# LKS32MC07x register map
Vendor: Linko Ltd.; Series: LKS32MC07x; File version: 1.0
CPU: CM0 r1p0, little endian, MPU, no FPU, 3 interrupt priority bits
Registers are 32-bit, read-write, reset 0x0 unless marked. A register's access mark holds for its fields unless they carry their own. Offsets are from the block's base; [hi:lo] are bit positions; {n}, {i} and the like mark numbered series; 'fields as' and 'values as' point back to an identical list.

## DMA0 — DMA0 registers
Base 0x40011200
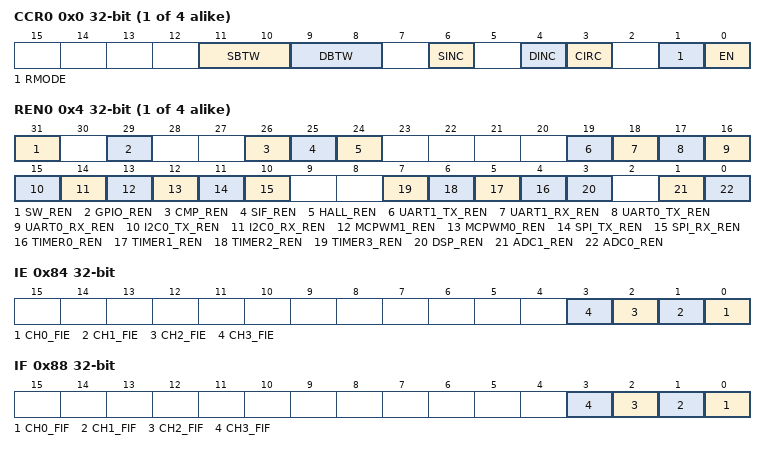
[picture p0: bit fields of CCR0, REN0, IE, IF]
{0x0+0x20*i} CCR{i} (i=0..3) — DMA channel {i} configuration
  [11:10] SBTW — Source data width
    0=BYTE (8bit byte); 1=HALFWORD (16bit halfword); 2=WORD (32bit word)
  [9:8] DBTW — Destination data width
    values as SBTW
  [6] SINC — Source Address Incremental
    0=NINC (Source addr will be increased by SBTW each transfer); 1=INC (Description addr will be increased by DBTW each transfer)
  [4] DINC — Destination Address Incremental
    values as SINC
  [3] CIRC — circular mode
    0=NORMAL (Normal mode); 1=CIRC (Circular mode)
  [1] RMODE — Round mode
    0=SINGLE (Single round, multi-times); 1=MULTI (Multi-round, single time per round)
  [0] EN — channel enable
    0=DISABLED (Channel is disabled); 1=ENABLED (Channel is enabled)
{0x4+0x20*i} REN{i} (i=0..3) — DMA channel {i} request enable
  [31] SW_REN — Software trigger enable
  [29] GPIO_REN — GPIO trigger enable
  [26] CMP_REN — CMP trigger enable
  [25] SIF_REN — SIF trigger enable
  [24] HALL_REN — HALL trigger enable
  [19] UART1_TX_REN — UART1_TX trigger enable
  [18] UART1_RX_REN — UART1_RX trigger enable
  [17] UART0_TX_REN — UART0_TX trigger enable
  [16] UART0_RX_REN — UART0_RX trigger enable
  [15] I2C0_TX_REN — I2C0_TX trigger enable
  [14] I2C0_RX_REN — I2C0_RX trigger enable
  [13] MCPWM1_REN — MCPWM trigger 1 enable
  [12] MCPWM0_REN — MCPWM trigger 0 enable
  [11] SPI_TX_REN — SPI_TX trigger enable
  [10] SPI_RX_REN — SPI_RX trigger enable
  [n+4] TIMER{n}_REN (n=0..3) — TIMER{n} trigger enable
  [3] DSP_REN — DSP trigger enable
  [1] ADC1_REN — ADC1 trigger enable
  [0] ADC0_REN — ADC0 trigger enable
{0x8+0x20*i} CTMS{i} (i=0..3) — DMA channel {i} transmission times
  [7:0] TMS — times or rounds
{0xC+0x20*i} SADR{i} (i=0..3) — DMA channel {i} source address
  [31:0] ADDR — Source Address
{0x10+0x20*i} DADR{i} (i=0..3) — DMA channel {i} destination address
  [31:0] ADDR — Destination Address
0x80 CTRL — DMA control
  [0] EN — DMA enable
    0=DISABLED (DMA is disabled); 1=ENABLED (DMA is enabled)
0x84 IE — DMA interrupt enable
  [n] CH{n}_FIE (n=0..3) — channel {n} transmission finish interrupt enable
0x88 IF — DMA interrupt flag
  [n] CH{n}_FIF (n=0..3) — channel {n} transmission finish interrupt flag

## SIF0 — SIF0 registers
Base 0x40011500
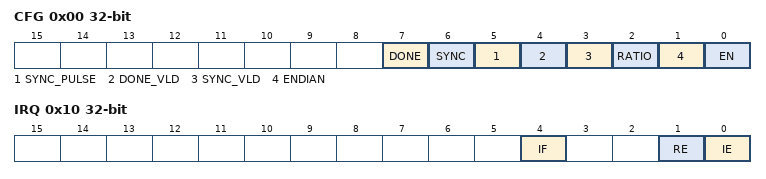
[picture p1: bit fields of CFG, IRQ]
0x00 CFG — SIF configuration register
  [7] DONE — Signal level after transmission
    0=L (Signal is low after transmission); 1=H (Signal is high after transmission)
  [6] SYNC — Sync siganl level
    0=L (Sync Signal is low); 1=H (Sync Signal is high)
  [5] SYNC_PULSE — Use pulse as sync signal
    0=NO (Don't use pulse as sync signal); 1=YES (Use pulse as sync sigal)
  [4] DONE_VLD — Done signal presence
    0=NO (There is no done signal); 1=YES (There is done signal)
  [3] SYNC_VLD — Sync signal presence
    0=NO (There is no sync signal); 1=YES (There is sync signal)
  [2] RATIO — Data duration
    0=3TO1 (3:1); 1=2TO1 (2:1)
  [1] ENDIAN — SIF LSB/MSB first
    0=LSB (LSB first); 1=MSB (MSB first)
  [0] EN — SIF module Enable
    0=DISABLED (SIF module is disabled); 1=ENABLED (SIF module is enabled)
0x04 TOSC — SIF timebase register
  [11:0] TOSC — Timer base
0x08 TSTH1 — SIF sync character period
  [9:0] TSTH — Character period
0x0C TDTH1 — SIF done character period
  [3:0] TDTH — Character period
0x10 IRQ — SIF interrupt register
  [4] IF — Interrupt Flag
    0=Clear (SIF interrupt is cleared); 1=Set (SIF interrupt is set)
  [1] RE — DMA Request Enable
    0=DISABLED (SIF DMA request is disabled); 1=ENABLED (SIF DMA request is enabled)
  [0] IE — Interrupt Enable
    0=DISABLED (SIF interrupt is disabled); 1=ENABLED (SIF interrupt is enabled)
0x14 WDATA — SIF write data register, write to start transmission
  [7:0] DAT — Data
